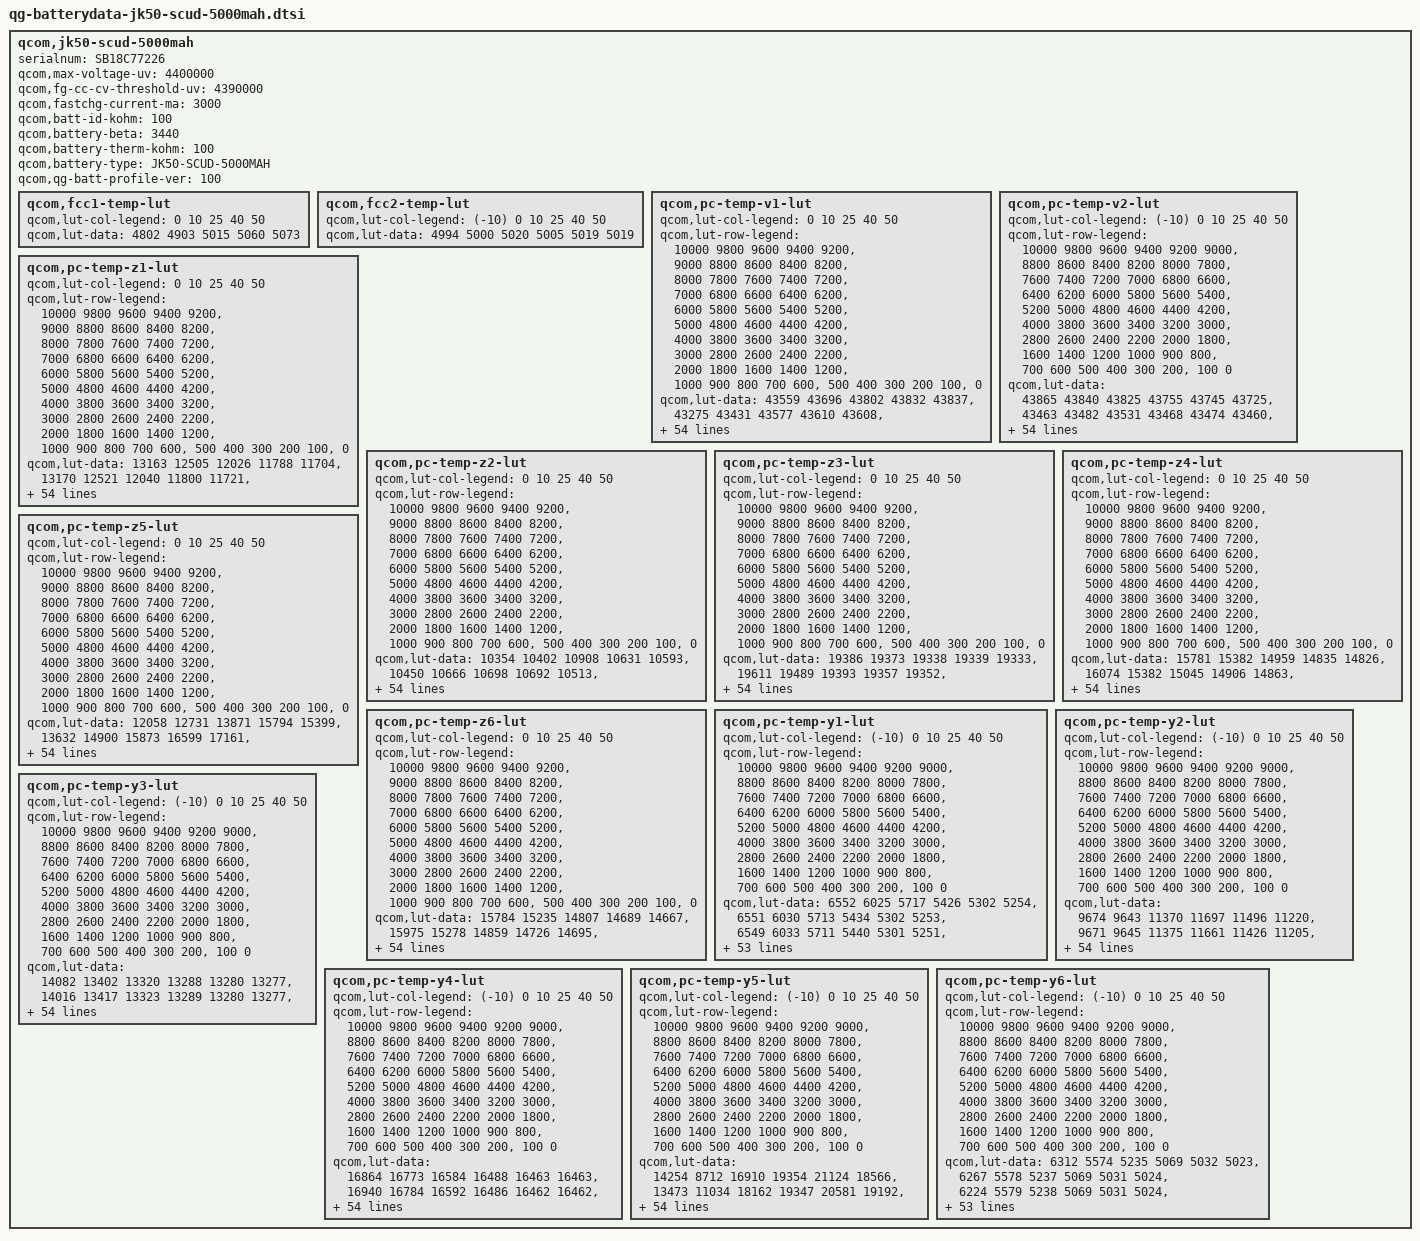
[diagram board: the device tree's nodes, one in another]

qcom,jk50-scud-5000mah {
    /* 4627739_Huaqin_QL1899_scud_5000mAH_PMI632_averaged_MasterSlave_Jun30th2020 */
    serialnum = "SB18C77226";
    qcom,max-voltage-uv = <4400000>;
    qcom,fg-cc-cv-threshold-uv = <4390000>;
    qcom,fastchg-current-ma = <3000>;
    qcom,batt-id-kohm = <100>;
    qcom,battery-beta = <3440>;
    qcom,battery-therm-kohm = <100>;
    qcom,battery-type = "JK50-SCUD-5000MAH";
    qcom,qg-batt-profile-ver = <100>;

	qcom,fcc1-temp-lut {
		qcom,lut-col-legend = <0 10 25 40 50>;
		qcom,lut-data = <4802 4903 5015 5060 5073>;
	};

	qcom,fcc2-temp-lut {
		qcom,lut-col-legend = <(-10) 0 10 25 40 50>;
		qcom,lut-data = <4994 5000 5020 5005 5019 5019>;
	};

	qcom,pc-temp-v1-lut {
		qcom,lut-col-legend = <0 10 25 40 50>;
		qcom,lut-row-legend = <10000 9800 9600 9400 9200>,
			<9000 8800 8600 8400 8200>,
			<8000 7800 7600 7400 7200>,
			<7000 6800 6600 6400 6200>,
			<6000 5800 5600 5400 5200>,
			<5000 4800 4600 4400 4200>,
			<4000 3800 3600 3400 3200>,
			<3000 2800 2600 2400 2200>,
			<2000 1800 1600 1400 1200>,
			<1000 900 800 700 600>,
			<500 400 300 200 100>,
			<0>;
		qcom,lut-data = <43559 43696 43802 43832 43837>,
			<43275 43431 43577 43610 43608>,
			<43022 43178 43333 43381 43382>,
			<42783 42938 43091 43149 43156>,
			<42550 42703 42850 42916 42926>,
			<42325 42468 42610 42678 42692>,
			<42107 42237 42374 42443 42458>,
			<41896 42014 42140 42207 42222>,
			<41693 41800 41911 41975 41989>,
			<41496 41592 41686 41747 41760>,
			<41307 41394 41467 41522 41533>,
			<41110 41204 41262 41301 41312>,
			<40897 41004 41064 41083 41095>,
			<40673 40787 40854 40871 40885>,
			<40434 40562 40622 40663 40679>,
			<40157 40330 40397 40463 40481>,
			<39919 40084 40202 40275 40290>,
			<39777 39893 40021 40098 40108>,
			<39672 39773 39860 39929 39933>,
			<39564 39670 39729 39776 39777>,
			<39447 39536 39582 39618 39620>,
			<39330 39378 39356 39400 39414>,
			<39209 39201 39080 39109 39139>,
			<39086 38974 38884 38895 38921>,
			<38959 38743 38746 38772 38793>,
			<38820 38605 38635 38674 38690>,
			<38680 38516 38545 38576 38581>,
			<38569 38449 38468 38483 38472>,
			<38476 38395 38395 38395 38376>,
			<38402 38350 38324 38312 38295>,
			<38355 38308 38260 38236 38222>,
			<38319 38267 38200 38167 38153>,
			<38287 38229 38146 38106 38088>,
			<38256 38196 38097 38049 38026>,
			<38229 38166 38056 37998 37969>,
			<38199 38134 38016 37949 37913>,
			<38171 38104 37981 37901 37857>,
			<38135 38067 37946 37854 37801>,
			<38081 38010 37893 37791 37731>,
			<38008 37924 37808 37702 37638>,
			<37916 37824 37707 37599 37533>,
			<37788 37706 37597 37489 37420>,
			<37648 37570 37470 37364 37292>,
			<37496 37409 37311 37208 37135>,
			<37357 37265 37168 37072 37004>,
			<37253 37168 37076 36989 36931>,
			<37216 37144 37050 36960 36902>,
			<37185 37124 37033 36944 36884>,
			<37158 37099 37016 36924 36863>,
			<37113 37059 36972 36870 36798>,
			<36927 36857 36744 36616 36520>,
			<36492 36421 36315 36181 36082>,
			<35925 35853 35745 35607 35510>,
			<35159 35079 34969 34824 34725>,
			<33947 33867 33761 33610 33505>,
			<30000 30000 30000 30000 30000>;
	};

	qcom,pc-temp-v2-lut {
		qcom,lut-col-legend = <(-10) 0 10 25 40 50>;
		qcom,lut-row-legend = <10000 9800 9600 9400 9200 9000>,
			<8800 8600 8400 8200 8000 7800>,
			<7600 7400 7200 7000 6800 6600>,
			<6400 6200 6000 5800 5600 5400>,
			<5200 5000 4800 4600 4400 4200>,
			<4000 3800 3600 3400 3200 3000>,
			<2800 2600 2400 2200 2000 1800>,
			<1600 1400 1200 1000 900 800>,
			<700 600 500 400 300 200>,
			<100 0>;
		qcom,lut-data = <43865 43840 43825 43755 43745 43725>,
			<43463 43482 43531 43468 43474 43460>,
			<43098 43159 43252 43196 43212 43203>,
			<42773 42876 42990 42938 42961 42956>,
			<42480 42631 42743 42697 42721 42720>,
			<42217 42392 42501 42460 42484 42486>,
			<41986 42149 42258 42224 42249 42251>,
			<41773 41907 42020 41992 42016 42017>,
			<41551 41649 41791 41763 41786 41787>,
			<41304 41363 41570 41538 41559 41559>,
			<41148 41147 41358 41318 41336 41336>,
			<41109 41046 41161 41109 41116 41116>,
			<41080 40964 40968 40904 40901 40901>,
			<40911 40792 40760 40691 40694 40693>,
			<40225 40445 40538 40468 40493 40490>,
			<39650 40101 40304 40257 40299 40295>,
			<39456 39840 40037 40062 40112 40109>,
			<39322 39607 39774 39881 39932 39931>,
			<39166 39409 39573 39720 39762 39762>,
			<38995 39241 39413 39582 39606 39605>,
			<38830 39073 39250 39424 39431 39429>,
			<38670 38886 39060 39189 39197 39197>,
			<38522 38699 38872 38933 38955 38957>,
			<38404 38533 38714 38747 38772 38775>,
			<38306 38378 38576 38604 38621 38623>,
			<38227 38256 38453 38481 38493 38494>,
			<38165 38169 38344 38373 38383 38383>,
			<38112 38100 38245 38277 38286 38285>,
			<38060 38045 38151 38188 38197 38194>,
			<38011 38001 38061 38108 38116 38110>,
			<37964 37962 37984 38035 38044 38036>,
			<37917 37925 37918 37965 37979 37970>,
			<37871 37889 37863 37901 37919 37908>,
			<37822 37851 37819 37843 37854 37841>,
			<37773 37812 37785 37791 37788 37770>,
			<37720 37770 37749 37739 37715 37689>,
			<37663 37725 37714 37684 37626 37584>,
			<37602 37676 37674 37626 37534 37475>,
			<37534 37617 37623 37560 37454 37389>,
			<37459 37548 37556 37486 37383 37317>,
			<37383 37467 37478 37404 37305 37239>,
			<37307 37364 37378 37309 37213 37147>,
			<37232 37248 37257 37199 37107 37041>,
			<37163 37127 37106 37067 36969 36904>,
			<37088 37016 36987 36948 36862 36800>,
			<36997 36933 36915 36891 36817 36761>,
			<36947 36903 36894 36876 36804 36751>,
			<36886 36869 36868 36862 36792 36738>,
			<36810 36813 36824 36835 36767 36708>,
			<36682 36714 36731 36770 36687 36605>,
			<36442 36494 36490 36547 36407 36290>,
			<36046 36071 36026 36076 35909 35789>,
			<35460 35453 35380 35465 35275 35141>,
			<34599 34571 34472 34629 34396 34239>,
			<33177 33157 33176 33350 33134 32938>,
			<29023 28472 28267 28203 28105 28098>;
	};

	qcom,pc-temp-z1-lut {
		qcom,lut-col-legend = <0 10 25 40 50>;
		qcom,lut-row-legend = <10000 9800 9600 9400 9200>,
			<9000 8800 8600 8400 8200>,
			<8000 7800 7600 7400 7200>,
			<7000 6800 6600 6400 6200>,
			<6000 5800 5600 5400 5200>,
			<5000 4800 4600 4400 4200>,
			<4000 3800 3600 3400 3200>,
			<3000 2800 2600 2400 2200>,
			<2000 1800 1600 1400 1200>,
			<1000 900 800 700 600>,
			<500 400 300 200 100>,
			<0>;
		qcom,lut-data = <13163 12505 12026 11788 11704>,
			<13170 12521 12040 11800 11721>,
			<13190 12526 12041 11800 11724>,
			<13206 12532 12038 11798 11723>,
			<13210 12537 12035 11795 11722>,
			<13211 12532 12030 11791 11720>,
			<13209 12518 12025 11788 11720>,
			<13205 12510 12018 11784 11720>,
			<13201 12505 12016 11783 11721>,
			<13196 12501 12015 11784 11723>,
			<13183 12502 12015 11785 11726>,
			<13170 12504 12018 11786 11728>,
			<13149 12502 12024 11788 11729>,
			<13117 12478 12025 11790 11730>,
			<13094 12451 12009 11788 11731>,
			<13075 12446 11994 11785 11731>,
			<13063 12444 11994 11785 11732>,
			<13062 12444 11995 11786 11733>,
			<13069 12445 11997 11787 11734>,
			<13074 12448 12004 11789 11736>,
			<13079 12456 12010 11791 11737>,
			<13083 12473 12013 11792 11738>,
			<13085 12484 12016 11792 11738>,
			<13086 12483 12017 11792 11739>,
			<13086 12481 12019 11794 11741>,
			<13091 12483 12022 11797 11743>,
			<13099 12491 12025 11799 11745>,
			<13101 12496 12029 11802 11748>,
			<13106 12496 12034 11805 11750>,
			<13109 12496 12039 11808 11753>,
			<13111 12496 12044 11811 11755>,
			<13115 12496 12047 11814 11758>,
			<13117 12497 12049 11818 11761>,
			<13127 12501 12052 11821 11764>,
			<13138 12509 12055 11826 11768>,
			<13144 12519 12058 11830 11771>,
			<13163 12535 12065 11833 11774>,
			<13179 12549 12073 11836 11776>,
			<13190 12556 12079 11839 11778>,
			<13200 12561 12086 11843 11780>,
			<13204 12562 12090 11846 11783>,
			<13195 12575 12093 11850 11785>,
			<13197 12583 12095 11853 11788>,
			<13214 12580 12099 11855 11790>,
			<13210 12579 12102 11860 11792>,
			<13222 12590 12102 11863 11793>,
			<13231 12585 12107 11863 11793>,
			<13204 12580 12113 11863 11794>,
			<13182 12574 12110 11866 11796>,
			<13212 12580 12112 11871 11801>,
			<13210 12599 12121 11877 11805>,
			<13224 12615 12130 11885 11812>,
			<13267 12645 12150 11898 11822>,
			<13274 12664 12167 11911 11836>,
			<13274 12664 12167 11911 11836>,
			<13274 12664 12167 11911 11836>;
	};

	qcom,pc-temp-z2-lut {
		qcom,lut-col-legend = <0 10 25 40 50>;
		qcom,lut-row-legend = <10000 9800 9600 9400 9200>,
			<9000 8800 8600 8400 8200>,
			<8000 7800 7600 7400 7200>,
			<7000 6800 6600 6400 6200>,
			<6000 5800 5600 5400 5200>,
			<5000 4800 4600 4400 4200>,
			<4000 3800 3600 3400 3200>,
			<3000 2800 2600 2400 2200>,
			<2000 1800 1600 1400 1200>,
			<1000 900 800 700 600>,
			<500 400 300 200 100>,
			<0>;
		qcom,lut-data = <10354 10402 10908 10631 10593>,
			<10450 10666 10698 10692 10513>,
			<10456 10723 10844 10723 10594>,
			<10461 10696 10895 10736 10655>,
			<10472 10661 10865 10728 10640>,
			<10481 10627 10823 10710 10605>,
			<10484 10591 10782 10690 10587>,
			<10479 10565 10739 10658 10561>,
			<10470 10544 10716 10634 10538>,
			<10460 10531 10702 10610 10535>,
			<10444 10530 10694 10582 10534>,
			<10424 10534 10698 10579 10534>,
			<10390 10540 10709 10603 10542>,
			<10351 10612 10718 10623 10549>,
			<10325 10716 10731 10633 10532>,
			<10302 10784 10740 10639 10499>,
			<10289 10843 10720 10618 10488>,
			<10304 10872 10679 10517 10486>,
			<10344 10813 10673 10461 10485>,
			<10376 10729 10732 10490 10491>,
			<10398 10730 10808 10550 10503>,
			<10416 10755 10884 10657 10555>,
			<10430 10768 10960 10850 10736>,
			<10441 10761 10965 10926 10825>,
			<10454 10749 10866 10767 10723>,
			<10475 10749 10788 10588 10610>,
			<10501 10763 10806 10610 10705>,
			<10521 10776 10850 10720 11042>,
			<10537 10779 10874 10779 11199>,
			<10552 10781 10888 10809 10982>,
			<10564 10786 10895 10824 10690>,
			<10574 10796 10897 10783 10564>,
			<10587 10807 10898 10711 10485>,
			<10605 10818 10899 10682 10447>,
			<10628 10830 10902 10676 10425>,
			<10654 10843 10908 10674 10416>,
			<10685 10860 10924 10700 10448>,
			<10720 10880 10951 10770 10533>,
			<10759 10903 10982 10822 10597>,
			<10800 10930 11025 10864 10638>,
			<10842 10954 11057 10891 10670>,
			<10885 10973 11068 10906 10694>,
			<10867 10998 11076 10921 10718>,
			<10526 11039 11082 10943 10774>,
			<10377 11308 11150 10931 10775>,
			<10312 11434 11204 10824 10651>,
			<10486 11528 11197 10791 10633>,
			<10977 11692 11195 10826 10645>,
			<11085 11832 11204 10851 10678>,
			<12143 11974 11284 10979 10824>,
			<10804 11815 11336 10905 10654>,
			<10359 11645 11284 10653 10406>,
			<10169 11455 11207 10561 10335>,
			<9840 11066 11187 10473 10267>,
			<9840 11066 11187 10473 10267>,
			<9840 11066 11187 10473 10267>;
	};

	qcom,pc-temp-z3-lut {
		qcom,lut-col-legend = <0 10 25 40 50>;
		qcom,lut-row-legend = <10000 9800 9600 9400 9200>,
			<9000 8800 8600 8400 8200>,
			<8000 7800 7600 7400 7200>,
			<7000 6800 6600 6400 6200>,
			<6000 5800 5600 5400 5200>,
			<5000 4800 4600 4400 4200>,
			<4000 3800 3600 3400 3200>,
			<3000 2800 2600 2400 2200>,
			<2000 1800 1600 1400 1200>,
			<1000 900 800 700 600>,
			<500 400 300 200 100>,
			<0>;
		qcom,lut-data = <19386 19373 19338 19339 19333>,
			<19611 19489 19393 19357 19352>,
			<19682 19533 19421 19376 19368>,
			<19716 19546 19433 19387 19379>,
			<19718 19553 19439 19393 19384>,
			<19711 19559 19442 19397 19388>,
			<19703 19563 19441 19400 19391>,
			<19692 19563 19441 19403 19396>,
			<19682 19558 19440 19404 19398>,
			<19677 19551 19439 19401 19397>,
			<19675 19546 19437 19395 19395>,
			<19675 19542 19433 19391 19391>,
			<19676 19539 19428 19388 19385>,
			<19677 19537 19425 19385 19379>,
			<19681 19536 19425 19383 19375>,
			<19696 19536 19423 19381 19371>,
			<19708 19535 19417 19377 19367>,
			<19689 19533 19408 19370 19364>,
			<19640 19506 19401 19363 19360>,
			<19615 19472 19396 19356 19354>,
			<19609 19470 19393 19350 19348>,
			<19606 19484 19400 19353 19347>,
			<19608 19497 19414 19366 19352>,
			<19619 19505 19416 19371 19353>,
			<19631 19511 19405 19355 19340>,
			<19644 19512 19394 19337 19324>,
			<19655 19511 19390 19337 19336>,
			<19657 19510 19388 19346 19386>,
			<19655 19507 19388 19355 19411>,
			<19651 19503 19392 19370 19403>,
			<19644 19500 19399 19383 19391>,
			<19634 19498 19405 19385 19384>,
			<19623 19496 19411 19383 19377>,
			<19613 19495 19413 19380 19370>,
			<19602 19493 19411 19374 19362>,
			<19590 19490 19408 19366 19354>,
			<19576 19486 19403 19360 19348>,
			<19563 19482 19397 19354 19343>,
			<19552 19479 19394 19352 19340>,
			<19543 19475 19392 19350 19337>,
			<19535 19471 19390 19349 19336>,
			<19529 19466 19386 19349 19339>,
			<19506 19459 19381 19350 19345>,
			<19395 19450 19379 19351 19349>,
			<19286 19419 19372 19349 19349>,
			<19262 19397 19364 19336 19333>,
			<19261 19351 19359 19334 19331>,
			<19259 19300 19351 19327 19321>,
			<19259 19292 19335 19323 19316>,
			<19259 19289 19332 19316 19314>,
			<19260 19301 19337 19325 19336>,
			<19261 19303 19327 19338 19349>,
			<19262 19299 19326 19340 19342>,
			<19265 19302 19317 19342 19342>,
			<19265 19302 19317 19342 19342>,
			<19265 19302 19317 19342 19342>;
	};

	qcom,pc-temp-z4-lut {
		qcom,lut-col-legend = <0 10 25 40 50>;
		qcom,lut-row-legend = <10000 9800 9600 9400 9200>,
			<9000 8800 8600 8400 8200>,
			<8000 7800 7600 7400 7200>,
			<7000 6800 6600 6400 6200>,
			<6000 5800 5600 5400 5200>,
			<5000 4800 4600 4400 4200>,
			<4000 3800 3600 3400 3200>,
			<3000 2800 2600 2400 2200>,
			<2000 1800 1600 1400 1200>,
			<1000 900 800 700 600>,
			<500 400 300 200 100>,
			<0>;
		qcom,lut-data = <15781 15382 14959 14835 14826>,
			<16074 15382 15045 14906 14863>,
			<15905 15351 15003 14885 14851>,
			<15699 15229 14959 14858 14832>,
			<15556 15097 14909 14834 14814>,
			<15427 15019 14862 14809 14794>,
			<15325 14956 14828 14786 14774>,
			<15245 14909 14801 14765 14756>,
			<15179 14872 14779 14747 14739>,
			<15121 14843 14760 14733 14724>,
			<15070 14818 14744 14720 14711>,
			<15026 14797 14730 14711 14704>,
			<14985 14777 14718 14704 14698>,
			<14950 14751 14712 14698 14694>,
			<14924 14730 14708 14691 14690>,
			<14904 14722 14705 14686 14687>,
			<14887 14717 14701 14682 14683>,
			<14873 14715 14695 14679 14679>,
			<14860 14716 14689 14677 14676>,
			<14845 14719 14679 14675 14673>,
			<14822 14715 14672 14674 14671>,
			<14797 14708 14700 14692 14685>,
			<14775 14704 14763 14762 14754>,
			<14753 14746 14794 14804 14800>,
			<14742 14811 14812 14815 14809>,
			<14747 14824 14821 14821 14814>,
			<14756 14817 14815 14814 14796>,
			<14762 14806 14798 14790 14727>,
			<14769 14793 14782 14764 14690>,
			<14774 14777 14763 14735 14687>,
			<14771 14762 14744 14709 14685>,
			<14761 14748 14727 14695 14681>,
			<14753 14736 14711 14686 14676>,
			<14745 14725 14703 14682 14674>,
			<14738 14714 14698 14681 14674>,
			<14734 14706 14694 14680 14675>,
			<14730 14698 14691 14680 14675>,
			<14728 14692 14689 14680 14676>,
			<14724 14692 14689 14681 14678>,
			<14721 14692 14694 14691 14691>,
			<14719 14692 14697 14699 14702>,
			<14718 14689 14693 14696 14696>,
			<14731 14686 14688 14689 14686>,
			<14833 14684 14685 14688 14688>,
			<14875 14673 14673 14679 14679>,
			<14879 14670 14655 14667 14665>,
			<14872 14713 14651 14661 14660>,
			<14869 14762 14647 14652 14653>,
			<14864 14765 14651 14635 14636>,
			<14858 14765 14649 14636 14627>,
			<14858 14757 14663 14661 14649>,
			<14878 14769 14686 14661 14652>,
			<14890 14779 14690 14663 14663>,
			<14905 14788 14705 14664 14664>,
			<14905 14788 14705 14664 14664>,
			<14905 14788 14705 14664 14664>;
	};

	qcom,pc-temp-z5-lut {
		qcom,lut-col-legend = <0 10 25 40 50>;
		qcom,lut-row-legend = <10000 9800 9600 9400 9200>,
			<9000 8800 8600 8400 8200>,
			<8000 7800 7600 7400 7200>,
			<7000 6800 6600 6400 6200>,
			<6000 5800 5600 5400 5200>,
			<5000 4800 4600 4400 4200>,
			<4000 3800 3600 3400 3200>,
			<3000 2800 2600 2400 2200>,
			<2000 1800 1600 1400 1200>,
			<1000 900 800 700 600>,
			<500 400 300 200 100>,
			<0>;
		qcom,lut-data = <12058 12731 13871 15794 15399>,
			<13632 14900 15873 16599 17161>,
			<14405 16087 17229 17915 18758>,
			<14909 16673 18141 18883 19853>,
			<15229 17208 18759 19449 20453>,
			<15475 18000 19297 19953 20996>,
			<15694 18882 19891 20656 21783>,
			<15888 19573 20487 21774 23233>,
			<16074 20059 21134 22603 24744>,
			<16330 20578 21868 22834 26035>,
			<16760 21389 22653 23041 27168>,
			<17164 22466 23539 23412 27598>,
			<17427 23485 24513 24304 27533>,
			<17681 24652 25378 25414 27519>,
			<18213 25923 27494 26940 27802>,
			<19739 27242 29063 28365 28227>,
			<20945 28767 27673 28279 28875>,
			<20268 29397 24784 26856 30193>,
			<18492 26656 24228 25967 31015>,
			<17776 22995 27216 25952 30599>,
			<18443 24660 31867 26104 29994>,
			<19775 35333 40394 28216 30526>,
			<21872 44677 51559 34805 32345>,
			<26049 49748 52917 37612 32192>,
			<31468 53474 40280 29227 25327>,
			<40547 53336 28442 19432 17661>,
			<50667 48441 25035 18178 19375>,
			<53939 43303 22930 18137 28724>,
			<54145 39960 22600 18582 33184>,
			<53414 37287 23373 21361 31694>,
			<50942 36717 24671 24948 30023>,
			<46279 37069 27574 27524 30345>,
			<42299 37672 32236 30110 31738>,
			<39433 38866 36033 31790 32292>,
			<36804 40764 39670 32929 31871>,
			<33954 42041 41636 33547 31281>,
			<30845 42816 41012 33270 30933>,
			<28834 43366 39557 32372 30653>,
			<28008 43746 38445 31390 30003>,
			<27471 44103 37679 30087 27448>,
			<27277 44128 36655 28860 25359>,
			<27322 41255 33760 27625 25779>,
			<26521 37758 31043 26598 27053>,
			<20292 35028 30864 27688 29320>,
			<13972 32911 32242 28208 30293>,
			<12373 28686 32034 24284 23772>,
			<12339 19908 29727 23834 22553>,
			<12304 13637 26229 22156 20417>,
			<12285 13290 20874 24443 22740>,
			<12333 13238 20975 22486 25061>,
			<12416 13895 20631 21376 26127>,
			<12308 13678 16893 20109 24423>,
			<12169 13284 16085 19120 19325>,
			<12013 13065 14667 17952 17595>,
			<12013 13065 14667 17952 17595>,
			<12013 13065 14667 17952 17595>;
	};

	qcom,pc-temp-z6-lut {
		qcom,lut-col-legend = <0 10 25 40 50>;
		qcom,lut-row-legend = <10000 9800 9600 9400 9200>,
			<9000 8800 8600 8400 8200>,
			<8000 7800 7600 7400 7200>,
			<7000 6800 6600 6400 6200>,
			<6000 5800 5600 5400 5200>,
			<5000 4800 4600 4400 4200>,
			<4000 3800 3600 3400 3200>,
			<3000 2800 2600 2400 2200>,
			<2000 1800 1600 1400 1200>,
			<1000 900 800 700 600>,
			<500 400 300 200 100>,
			<0>;
		qcom,lut-data = <15784 15235 14807 14689 14667>,
			<15975 15278 14859 14726 14695>,
			<15905 15277 14857 14726 14697>,
			<15812 15219 14852 14725 14697>,
			<15732 15150 14831 14720 14695>,
			<15651 15109 14806 14709 14687>,
			<15583 15074 14789 14700 14681>,
			<15529 15045 14775 14693 14675>,
			<15483 15020 14764 14686 14670>,
			<15445 14998 14754 14677 14664>,
			<15414 14980 14746 14670 14658>,
			<15383 14965 14738 14664 14652>,
			<15349 14948 14731 14659 14647>,
			<15317 14927 14725 14655 14642>,
			<15297 14909 14720 14651 14638>,
			<15287 14902 14715 14647 14634>,
			<15275 14899 14709 14642 14630>,
			<15253 14895 14703 14637 14626>,
			<15223 14881 14697 14633 14623>,
			<15200 14867 14691 14628 14618>,
			<15183 14866 14688 14625 14614>,
			<15172 14871 14704 14634 14620>,
			<15171 14879 14739 14672 14653>,
			<15170 14904 14753 14691 14672>,
			<15170 14935 14755 14688 14669>,
			<15178 14941 14755 14683 14665>,
			<15193 14939 14751 14678 14663>,
			<15200 14936 14744 14674 14661>,
			<15203 14930 14738 14669 14659>,
			<15205 14922 14734 14665 14654>,
			<15202 14916 14730 14661 14648>,
			<15195 14910 14726 14657 14642>,
			<15187 14905 14724 14653 14637>,
			<15181 14900 14722 14649 14633>,
			<15175 14897 14719 14646 14629>,
			<15169 14894 14717 14643 14625>,
			<15163 14891 14714 14640 14622>,
			<15161 14889 14711 14637 14620>,
			<15160 14890 14711 14636 14619>,
			<15161 14892 14713 14639 14623>,
			<15161 14893 14714 14642 14626>,
			<15163 14892 14712 14641 14626>,
			<15163 14892 14709 14640 14625>,
			<15162 14892 14708 14640 14628>,
			<15138 14880 14702 14636 14625>,
			<15129 14871 14692 14624 14611>,
			<15127 14867 14688 14621 14607>,
			<15126 14862 14683 14613 14599>,
			<15124 14860 14677 14604 14589>,
			<15126 14863 14676 14601 14584>,
			<15135 14872 14687 14618 14607>,
			<15151 14884 14695 14627 14617>,
			<15170 14895 14701 14632 14621>,
			<15194 14912 14709 14638 14626>,
			<15194 14912 14709 14638 14626>,
			<15194 14912 14709 14638 14626>;
	};

	qcom,pc-temp-y1-lut {
		qcom,lut-col-legend = <(-10) 0 10 25 40 50>;
		qcom,lut-row-legend = <10000 9800 9600 9400 9200 9000>,
			<8800 8600 8400 8200 8000 7800>,
			<7600 7400 7200 7000 6800 6600>,
			<6400 6200 6000 5800 5600 5400>,
			<5200 5000 4800 4600 4400 4200>,
			<4000 3800 3600 3400 3200 3000>,
			<2800 2600 2400 2200 2000 1800>,
			<1600 1400 1200 1000 900 800>,
			<700 600 500 400 300 200>,
			<100 0>;
		qcom,lut-data = <6552 6025 5717 5426 5302 5254>,
			<6551 6030 5713 5434 5302 5253>,
			<6549 6033 5711 5440 5301 5251>,
			<6548 6035 5708 5442 5300 5250>,
			<6548 6035 5707 5443 5299 5249>,
			<6549 6035 5706 5443 5297 5248>,
			<6552 6033 5707 5441 5295 5248>,
			<6555 6031 5709 5437 5293 5248>,
			<6556 6032 5709 5435 5292 5248>,
			<6552 6038 5706 5434 5290 5247>,
			<6550 6045 5703 5432 5289 5246>,
			<6559 6049 5701 5431 5288 5245>,
			<6573 6053 5699 5430 5287 5245>,
			<6576 6056 5699 5430 5287 5245>,
			<6574 6063 5703 5430 5286 5245>,
			<6571 6066 5707 5430 5286 5245>,
			<6569 6063 5714 5432 5287 5245>,
			<6565 6058 5722 5435 5288 5246>,
			<6561 6056 5724 5436 5288 5246>,
			<6554 6060 5722 5436 5288 5247>,
			<6549 6064 5720 5437 5288 5247>,
			<6559 6067 5716 5437 5288 5247>,
			<6575 6070 5712 5439 5289 5248>,
			<6575 6068 5713 5440 5290 5249>,
			<6559 6060 5717 5443 5292 5251>,
			<6549 6056 5719 5445 5293 5253>,
			<6545 6060 5718 5449 5295 5254>,
			<6540 6065 5716 5453 5297 5255>,
			<6538 6064 5716 5454 5300 5257>,
			<6537 6056 5716 5455 5303 5259>,
			<6536 6050 5717 5456 5306 5261>,
			<6545 6053 5718 5459 5308 5263>,
			<6559 6059 5720 5463 5310 5265>,
			<6561 6059 5722 5464 5312 5267>,
			<6557 6053 5725 5465 5315 5268>,
			<6553 6050 5726 5466 5318 5269>,
			<6545 6054 5725 5468 5320 5271>,
			<6533 6058 5724 5470 5321 5273>,
			<6529 6057 5725 5473 5322 5275>,
			<6533 6049 5730 5476 5324 5277>,
			<6538 6044 5731 5478 5325 5278>,
			<6536 6056 5729 5478 5328 5279>,
			<6536 6068 5730 5478 5331 5281>,
			<6559 6060 5733 5481 5334 5284>,
			<6558 6073 5739 5488 5340 5288>,
			<6597 6100 5749 5495 5343 5291>,
			<6613 6085 5743 5497 5343 5290>,
			<6595 6083 5748 5499 5343 5289>,
			<6629 6112 5759 5494 5341 5288>,
			<6623 6105 5761 5501 5341 5289>,
			<6601 6106 5763 5499 5343 5292>,
			<6634 6135 5767 5513 5349 5297>,
			<6651 6155 5781 5519 5359 5303>,
			<6676 6155 5801 5542 5370 5313>,
			<6676 6155 5801 5542 5370 5313>,
			<6676 6155 5801 5542 5370 5313>;
	};

	qcom,pc-temp-y2-lut {
		qcom,lut-col-legend = <(-10) 0 10 25 40 50>;
		qcom,lut-row-legend = <10000 9800 9600 9400 9200 9000>,
			<8800 8600 8400 8200 8000 7800>,
			<7600 7400 7200 7000 6800 6600>,
			<6400 6200 6000 5800 5600 5400>,
			<5200 5000 4800 4600 4400 4200>,
			<4000 3800 3600 3400 3200 3000>,
			<2800 2600 2400 2200 2000 1800>,
			<1600 1400 1200 1000 900 800>,
			<700 600 500 400 300 200>,
			<100 0>;
		qcom,lut-data = <9674 9643 11370 11697 11496 11220>,
			<9671 9645 11375 11661 11426 11205>,
			<9669 9962 11368 11624 11356 11182>,
			<9669 10281 11350 11587 11292 11152>,
			<9671 10522 11324 11550 11235 11121>,
			<9672 10617 11292 11513 11191 11089>,
			<9676 10566 11241 11474 11159 11050>,
			<9681 10488 11191 11436 11132 11011>,
			<9681 10494 11179 11405 11102 10991>,
			<9677 10609 11182 11380 11068 10978>,
			<9675 10692 11180 11353 11052 10970>,
			<9676 10686 11125 11310 11080 10975>,
			<9678 10668 11052 11270 11120 10985>,
			<9678 10691 11105 11270 11130 10980>,
			<9675 10787 11389 11307 11131 10958>,
			<9673 10898 11552 11358 11135 10946>,
			<9673 11007 11540 11438 11177 11003>,
			<9673 11116 11521 11548 11255 11105>,
			<9673 11192 11509 11662 11366 11192>,
			<9672 11252 11496 11796 11552 11283>,
			<9672 11290 11491 11861 11644 11332>,
			<9672 11074 11539 11794 11602 11322>,
			<9671 10699 11609 11695 11539 11300>,
			<9671 10513 11636 11684 11496 11296>,
			<9670 10080 11648 11715 11423 11295>,
			<9670 9795 11661 11751 11388 11295>,
			<9669 9763 11682 11785 11444 11355>,
			<9669 9745 11701 11819 11525 11442>,
			<9668 9733 11709 11840 11564 11488>,
			<9667 9721 11716 11857 11603 11522>,
			<9667 9710 11719 11865 11628 11548>,
			<9666 9702 11720 11866 11713 11628>,
			<9666 9695 11720 11866 11811 11711>,
			<9665 9689 11709 11859 11829 11700>,
			<9665 9684 11673 11840 11833 11634>,
			<9664 9679 11629 11819 11818 11574>,
			<9664 9675 11573 11793 11681 11540>,
			<9663 9672 11507 11765 11529 11525>,
			<9663 9669 11447 11739 11514 11515>,
			<9663 9667 11388 11703 11519 11483>,
			<9663 9665 11315 11668 11526 11449>,
			<9662 9663 11230 11638 11547 11421>,
			<9662 9662 11060 11606 11553 11404>,
			<9662 9661 10379 11570 11428 11356>,
			<9662 9660 9940 11466 11304 11162>,
			<9662 9661 9898 11433 11192 11003>,
			<9661 9660 9818 11406 11197 11027>,
			<9661 9660 9773 11386 11276 11130>,
			<9661 9660 9738 11377 11311 11147>,
			<9660 9659 9717 11380 11333 11102>,
			<9660 9659 9703 11376 11241 10988>,
			<9660 9658 9692 11274 11123 10889>,
			<9659 9658 9677 11131 11046 10796>,
			<9658 9657 9668 11035 10915 10670>,
			<9658 9657 9668 11035 10915 10670>,
			<9658 9657 9668 11035 10915 10670>;
	};

	qcom,pc-temp-y3-lut {
		qcom,lut-col-legend = <(-10) 0 10 25 40 50>;
		qcom,lut-row-legend = <10000 9800 9600 9400 9200 9000>,
			<8800 8600 8400 8200 8000 7800>,
			<7600 7400 7200 7000 6800 6600>,
			<6400 6200 6000 5800 5600 5400>,
			<5200 5000 4800 4600 4400 4200>,
			<4000 3800 3600 3400 3200 3000>,
			<2800 2600 2400 2200 2000 1800>,
			<1600 1400 1200 1000 900 800>,
			<700 600 500 400 300 200>,
			<100 0>;
		qcom,lut-data = <14082 13402 13320 13288 13280 13277>,
			<14016 13417 13323 13289 13280 13277>,
			<13949 13427 13326 13289 13281 13278>,
			<13886 13433 13329 13290 13281 13279>,
			<13832 13436 13332 13291 13281 13279>,
			<13793 13436 13334 13292 13281 13280>,
			<13771 13429 13335 13292 13282 13280>,
			<13752 13420 13336 13293 13282 13280>,
			<13706 13420 13337 13293 13283 13281>,
			<13598 13428 13339 13293 13283 13281>,
			<13533 13434 13341 13293 13284 13282>,
			<13531 13400 13345 13295 13284 13282>,
			<13531 13348 13349 13298 13284 13283>,
			<13527 13343 13347 13301 13286 13284>,
			<13510 13368 13338 13303 13289 13284>,
			<13494 13384 13333 13303 13291 13284>,
			<13485 13381 13332 13301 13292 13286>,
			<13477 13376 13332 13298 13292 13288>,
			<13476 13371 13330 13298 13291 13289>,
			<13477 13366 13326 13301 13291 13289>,
			<13477 13360 13322 13302 13290 13289>,
			<13475 13353 13318 13298 13287 13285>,
			<13471 13344 13315 13293 13283 13280>,
			<13471 13335 13313 13290 13281 13278>,
			<13474 13323 13310 13288 13279 13277>,
			<13479 13312 13309 13287 13278 13276>,
			<13490 13300 13309 13287 13278 13277>,
			<13508 13289 13308 13286 13278 13277>,
			<13526 13289 13307 13286 13278 13277>,
			<13543 13296 13306 13287 13277 13276>,
			<13564 13307 13304 13287 13277 13276>,
			<13589 13321 13302 13287 13278 13276>,
			<13620 13340 13300 13287 13278 13276>,
			<13654 13357 13300 13287 13278 13276>,
			<13693 13373 13302 13287 13279 13276>,
			<13734 13393 13304 13287 13279 13277>,
			<13777 13421 13306 13287 13278 13276>,
			<13820 13457 13310 13287 13277 13275>,
			<13860 13499 13312 13287 13277 13276>,
			<13897 13551 13315 13288 13279 13278>,
			<13934 13609 13317 13288 13280 13280>,
			<13971 13672 13319 13289 13281 13280>,
			<14011 13740 13319 13290 13281 13280>,
			<14052 13812 13314 13290 13279 13278>,
			<14102 13889 13325 13291 13279 13278>,
			<14062 13871 13326 13292 13282 13283>,
			<14101 13924 13338 13293 13285 13287>,
			<14150 13974 13348 13299 13290 13289>,
			<14207 14029 13362 13303 13293 13290>,
			<14262 14085 13381 13305 13293 13288>,
			<14329 14134 13393 13303 13287 13284>,
			<14406 14183 13408 13300 13285 13284>,
			<14515 14274 13455 13307 13289 13287>,
			<14777 14391 13538 13316 13297 13293>,
			<14777 14391 13538 13316 13297 13293>,
			<14777 14391 13538 13316 13297 13293>;
	};

	qcom,pc-temp-y4-lut {
		qcom,lut-col-legend = <(-10) 0 10 25 40 50>;
		qcom,lut-row-legend = <10000 9800 9600 9400 9200 9000>,
			<8800 8600 8400 8200 8000 7800>,
			<7600 7400 7200 7000 6800 6600>,
			<6400 6200 6000 5800 5600 5400>,
			<5200 5000 4800 4600 4400 4200>,
			<4000 3800 3600 3400 3200 3000>,
			<2800 2600 2400 2200 2000 1800>,
			<1600 1400 1200 1000 900 800>,
			<700 600 500 400 300 200>,
			<100 0>;
		qcom,lut-data = <16864 16773 16584 16488 16463 16463>,
			<16940 16784 16592 16486 16462 16462>,
			<17008 16799 16603 16485 16461 16461>,
			<17064 16815 16614 16485 16461 16460>,
			<17101 16831 16623 16486 16461 16460>,
			<17115 16846 16627 16487 16462 16460>,
			<17097 16865 16626 16489 16463 16460>,
			<17071 16885 16624 16492 16465 16461>,
			<17092 16883 16626 16496 16467 16462>,
			<17254 16856 16636 16503 16470 16464>,
			<17432 16839 16649 16509 16473 16466>,
			<17584 17040 16658 16511 16477 16468>,
			<17710 17349 16670 16513 16481 16470>,
			<17643 17366 16702 16518 16485 16474>,
			<17156 17132 16774 16530 16489 16479>,
			<16831 16924 16812 16546 16493 16485>,
			<16840 16823 16753 16569 16501 16489>,
			<16856 16752 16670 16596 16514 16495>,
			<16854 16733 16651 16617 16533 16508>,
			<16821 16728 16648 16636 16565 16535>,
			<16784 16721 16642 16645 16580 16549>,
			<16752 16696 16609 16595 16547 16526>,
			<16723 16660 16564 16516 16499 16491>,
			<16714 16637 16545 16489 16478 16475>,
			<16710 16619 16533 16478 16466 16464>,
			<16708 16611 16526 16474 16461 16460>,
			<16706 16619 16523 16475 16462 16461>,
			<16705 16632 16519 16477 16466 16462>,
			<16705 16636 16514 16480 16470 16465>,
			<16711 16636 16505 16485 16478 16473>,
			<16717 16636 16500 16489 16486 16481>,
			<16722 16635 16499 16491 16497 16492>,
			<16726 16633 16499 16493 16506 16502>,
			<16730 16636 16501 16494 16507 16505>,
			<16734 16649 16507 16494 16504 16506>,
			<16737 16662 16514 16493 16500 16506>,
			<16739 16671 16523 16490 16484 16487>,
			<16740 16679 16534 16485 16467 16464>,
			<16740 16686 16543 16482 16466 16463>,
			<16740 16691 16552 16480 16468 16469>,
			<16741 16693 16559 16479 16472 16475>,
			<16750 16686 16565 16485 16477 16481>,
			<16765 16674 16572 16489 16479 16483>,
			<16785 16661 16589 16485 16464 16460>,
			<16806 16661 16591 16482 16455 16451>,
			<16778 16656 16587 16481 16464 16468>,
			<16787 16667 16602 16495 16485 16493>,
			<16807 16687 16627 16511 16511 16525>,
			<16829 16721 16662 16543 16547 16558>,
			<16858 16768 16699 16572 16553 16554>,
			<16843 16781 16704 16551 16501 16491>,
			<16825 16756 16688 16513 16475 16473>,
			<16825 16747 16700 16524 16477 16473>,
			<16909 16762 16749 16547 16485 16479>,
			<16909 16762 16749 16547 16485 16479>,
			<16909 16762 16749 16547 16485 16479>;
	};

	qcom,pc-temp-y5-lut {
		qcom,lut-col-legend = <(-10) 0 10 25 40 50>;
		qcom,lut-row-legend = <10000 9800 9600 9400 9200 9000>,
			<8800 8600 8400 8200 8000 7800>,
			<7600 7400 7200 7000 6800 6600>,
			<6400 6200 6000 5800 5600 5400>,
			<5200 5000 4800 4600 4400 4200>,
			<4000 3800 3600 3400 3200 3000>,
			<2800 2600 2400 2200 2000 1800>,
			<1600 1400 1200 1000 900 800>,
			<700 600 500 400 300 200>,
			<100 0>;
		qcom,lut-data = <14254 8712 16910 19354 21124 18566>,
			<13473 11034 18162 19347 20581 19192>,
			<13131 13520 18919 19226 19997 19505>,
			<13127 15637 19306 19020 19406 19577>,
			<13358 17110 19448 18756 18844 19482>,
			<13726 17663 19466 18461 18347 19291>,
			<14779 17301 19124 18045 17889 18859>,
			<16082 16503 18495 17490 17448 18243>,
			<15892 15517 18056 16824 17039 17742>,
			<13536 14014 17735 15877 16597 17269>,
			<11985 13197 17317 15332 16182 16898>,
			<14423 13327 16321 15447 15737 16672>,
			<18288 13692 15281 15679 15377 16470>,
			<18554 15244 15228 15663 15431 16113>,
			<15747 20961 15850 15506 15896 15527>,
			<13869 24537 16825 15345 16164 15238>,
			<13976 23438 19699 15172 15814 15443>,
			<14207 21738 22966 15053 15325 15763>,
			<14418 21613 23515 15729 15314 15849>,
			<14695 22633 23340 18889 15685 15706>,
			<14846 23332 23313 21556 16296 15743>,
			<14466 22135 23651 22863 18587 17406>,
			<13736 19968 23995 23753 21201 19476>,
			<13242 18548 23896 23716 21356 19701>,
			<12842 15825 23349 22900 20459 19427>,
			<12648 13762 23069 22190 19603 19155>,
			<12740 12945 23483 21808 18961 18872>,
			<12904 12426 24001 21532 18449 18565>,
			<12921 12347 23972 21514 18194 18128>,
			<12829 12473 23508 21852 18004 17162>,
			<12766 12626 22825 22193 17942 16687>,
			<12833 12994 21242 22626 18372 16798>,
			<12982 13478 19545 23232 19163 17046>,
			<13146 13583 19101 23758 20251 17737>,
			<13374 13589 19210 24289 21995 19416>,
			<13581 13599 19511 24526 22747 20579>,
			<13768 13800 20022 24173 21810 21013>,
			<13932 14137 20465 23559 20692 21263>,
			<13941 14331 20452 23020 20803 21666>,
			<13775 14468 20215 22220 21583 22537>,
			<13558 14527 19897 21409 21940 22873>,
			<13250 14488 19247 20730 21379 21716>,
			<13025 14408 18077 20090 20550 20870>,
			<13139 14308 15011 19384 19396 21078>,
			<13304 13852 14641 19206 18772 18980>,
			<13446 13713 14212 18867 17281 17743>,
			<13668 14055 14425 17731 16928 17474>,
			<13774 14167 14190 18527 17662 17049>,
			<14160 14047 13977 18504 17465 16374>,
			<14186 14178 14404 18279 17346 15738>,
			<14384 14508 14555 18144 16996 15773>,
			<14285 14328 14377 18781 17137 16436>,
			<14135 14055 14180 19780 17902 16504>,
			<13309 13852 14135 21101 22953 20979>,
			<13309 13852 14135 21101 22953 20979>,
			<13309 13852 14135 21101 22953 20979>;
	};

	qcom,pc-temp-y6-lut {
		qcom,lut-col-legend = <(-10) 0 10 25 40 50>;
		qcom,lut-row-legend = <10000 9800 9600 9400 9200 9000>,
			<8800 8600 8400 8200 8000 7800>,
			<7600 7400 7200 7000 6800 6600>,
			<6400 6200 6000 5800 5600 5400>,
			<5200 5000 4800 4600 4400 4200>,
			<4000 3800 3600 3400 3200 3000>,
			<2800 2600 2400 2200 2000 1800>,
			<1600 1400 1200 1000 900 800>,
			<700 600 500 400 300 200>,
			<100 0>;
		qcom,lut-data = <6312 5574 5235 5069 5032 5023>,
			<6267 5578 5237 5069 5031 5024>,
			<6224 5579 5238 5069 5031 5024>,
			<6184 5580 5238 5069 5031 5025>,
			<6147 5580 5237 5069 5031 5025>,
			<6115 5580 5236 5069 5032 5025>,
			<6086 5574 5233 5069 5032 5026>,
			<6061 5562 5229 5070 5033 5026>,
			<6038 5550 5228 5071 5034 5027>,
			<6015 5535 5229 5072 5035 5028>,
			<6004 5527 5229 5073 5036 5029>,
			<6031 5556 5231 5075 5037 5030>,
			<6073 5601 5235 5078 5039 5031>,
			<6055 5602 5240 5081 5041 5033>,
			<5911 5558 5252 5085 5044 5034>,
			<5814 5515 5257 5090 5047 5036>,
			<5813 5489 5243 5095 5050 5039>,
			<5812 5469 5220 5101 5053 5042>,
			<5810 5459 5211 5107 5059 5046>,
			<5802 5454 5207 5113 5067 5054>,
			<5794 5448 5202 5116 5071 5057>,
			<5786 5435 5189 5100 5059 5048>,
			<5779 5420 5175 5073 5042 5034>,
			<5778 5410 5168 5064 5034 5028>,
			<5781 5402 5164 5060 5029 5024>,
			<5786 5398 5163 5058 5028 5022>,
			<5795 5401 5163 5059 5028 5023>,
			<5809 5409 5163 5060 5029 5023>,
			<5824 5418 5162 5061 5031 5024>,
			<5840 5431 5161 5063 5033 5026>,
			<5858 5448 5160 5065 5035 5028>,
			<5881 5467 5161 5066 5039 5032>,
			<5906 5490 5162 5068 5042 5035>,
			<5934 5515 5165 5069 5043 5036>,
			<5965 5543 5172 5070 5043 5037>,
			<5998 5574 5180 5070 5042 5037>,
			<6031 5611 5189 5070 5037 5031>,
			<6065 5653 5201 5069 5031 5025>,
			<6096 5698 5213 5070 5031 5025>,
			<6125 5748 5228 5070 5034 5028>,
			<6155 5799 5244 5072 5036 5031>,
			<6187 5851 5262 5075 5038 5033>,
			<6222 5905 5282 5078 5039 5034>,
			<6262 5958 5303 5079 5033 5026>,
			<6308 6021 5333 5083 5033 5025>,
			<6281 6012 5332 5085 5038 5034>,
			<6314 6053 5358 5091 5046 5043>,
			<6360 6098 5384 5101 5057 5055>,
			<6409 6153 5417 5112 5069 5064>,
			<6462 6211 5455 5122 5070 5062>,
			<6515 6257 5477 5115 5052 5041>,
			<6578 6292 5502 5105 5044 5036>,
			<6673 6365 5585 5121 5049 5040>,
			<6932 6469 5698 5141 5059 5048>,
			<6932 6469 5698 5141 5059 5048>,
			<6932 6469 5698 5141 5059 5048>;
	};

};
